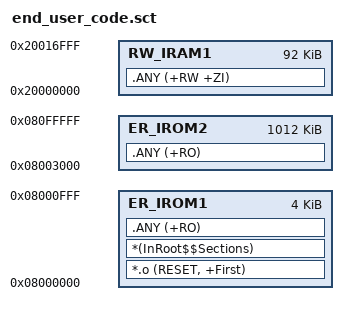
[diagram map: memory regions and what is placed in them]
; *************************************************************
; *** Scatter-Loading Description File generated by uVision ***
; *************************************************************

LR_IROM1 0x08000000 0x00001000  {    ; load region size_region
  ER_IROM1 0x08000000 0x00001000  {  ; load address = execution address
   *.o (RESET, +First)
   *(InRoot$$Sections)
   .ANY (+RO)
  }
  RW_IRAM1 0x20000000 0x00017000  {  ; RW data
   .ANY (+RW +ZI)
  }
  
 ; 0x20017000 ~ 0x20017FFF   RAM reserved for SLIB code
  
}

; 0x08001000 ~ 0x08002FFF is SLIB area

LR_IROM2 0x08003000 0x000FD000  {    ; load region size_region
  ER_IROM2 0x08003000 0x000FD000  {  ; load address = execution address
   .ANY (+RO)
  }
}



